# Keyboard_Controller register map
Vendor: Texas Instruments
Peripheral module from a debugger description file (folder omap4460).
Registers are 32-bit, read-only, reset 0x0 unless marked. A register's access mark holds for its fields unless they carry their own. Offsets are as the file gives them; lines under a group give offsets from that group; [hi:lo] are bit positions; {n}, {i} and the like mark numbered series; 'fields as' and 'values as' point back to an identical list; <NAME> marks a mode.

## Keyboard_Controller
0x00 KBD_REVISION reset not defined — This register contains the IP revision code.
  [31:0] REVISION — IP revision
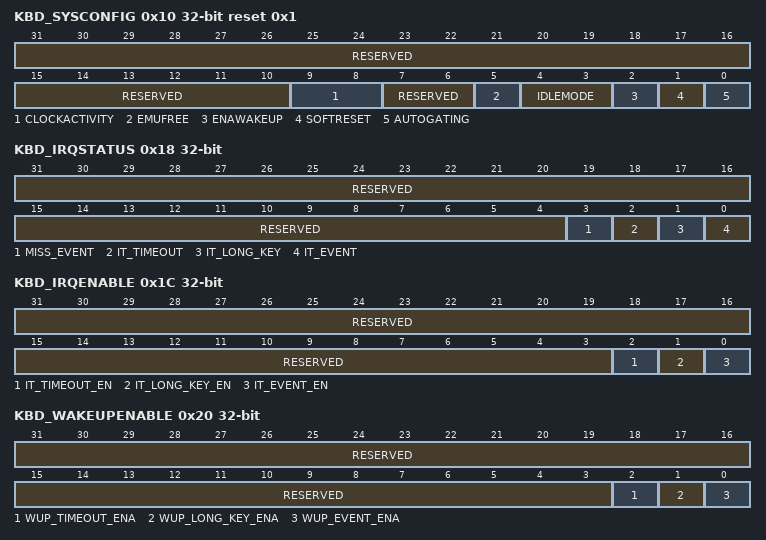
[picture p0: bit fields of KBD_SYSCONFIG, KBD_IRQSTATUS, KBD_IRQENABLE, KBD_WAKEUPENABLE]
0x10 KBD_SYSCONFIG rw reset 0x1 — This register controls the various parameters of the L4 interface.
  [31:10] RESERVED — Reads return 0.
  [9:8] CLOCKACTIVITY — Clock(s) activity during wake-up mode period.
    0=Functional clock can be switched off; L4 -nterface clock can be switched-off; 1=Functional clock can be switched off; L4 interface clock is maintained during wake-up period; 2=Functional clock is maintained during wake-up period; L4 interface clock can be switched off; 3=Functional clock is maintained during wake-up period; L4 interface clock is maintained during wake-up period
  [7:6] RESERVED — Write 0s for future compatibility.Reads return 0.
  [5] EMUFREE — Emulation mode
    0=The keyboard module is frozen in emulation mode (PINSUSPENDN signal active); 1=The keyboard module runs free, regardless of PINSUSPENDN value
  [4:3] IDLEMODE — Power management, req/ack control
    0=Force-idle. An idle request is acknowledged unconditionally.; 1=No-idle. An idle request is never acknowledged.; 2=Smart-idle. Acknowledgment to an idle request is given based on the internal activity of the module.; 3=Reserved.Do not use
  [2] ENAWAKEUP — Wake-up feature global control
    0=No wake-up line assertion in idle mode; 1=Wake-up line assertion enabled in smart-idle mode
  [1] SOFTRESET — Software reset. This bit is automatically reset by the hardware. During reads, it always return 0.
    0=Normal mode; 1=The module is reset
  [0] AUTOGATING — Internal L4 interface clock gating strategy
    0=L4 interface clock is free-running; 1=Automatic L4 interface clock gating strategy is applied, based on the L4 interface activity
0x14 KBD_SYSSTATUS — This register controls optional features specific to the timer function.
  [0] RESETDONE — Internal reset monitoring
    0=RESETDONE_0_r (Internal module reset is ongoing.); 1=RESETDONE_1_r (Reset completed)
0x18 KBD_IRQSTATUS rw — The keyboard interrupt-status register is used to determine which of the keyboard events requested an interrupt.
  [31:4] RESERVED — Reads return 0.
  [3] MISS_EVENT — Indicates when a miss event occurs.
    0=No miss event; 1=A miss event occurs
  [2] IT_TIMEOUT — Indicates when a time-out event is detected.
    0=No time-out event; 1=A time-out event occurs
  [1] IT_LONG_KEY — Indicates when a long-key event is detected.
    0=No long-key event; 1=A long-key event occurs
  [0] IT_EVENT — Indicates when an event is detected.
    0=No event; 1=An event occurs
0x1C KBD_IRQENABLE rw — The keyboard interrupt-enable register lets the user enable certain keyboard event for generating an interrupt request.
  [31:3] RESERVED — Reads return 0
  [2] IT_TIMEOUT_EN — Time-out interrupt enable
    0=Time-out interrupt disabled; 1=Time-out interrupt enabled
  [1] IT_LONG_KEY_EN — Long-key interrupt enable
    0=Long-key interrupt disabled; 1=Long-key interrupt enabled
  [0] IT_EVENT_EN — Enable event interrupt
    0=Event interrupt disabled; 1=Event interrupt enabled
0x20 KBD_WAKEUPENABLE rw — The keyboard wake-up enable register lets the user mask the expected source of wake-up event that generates a wake-up request.
  [31:3] RESERVED — Reads return 0.
  [2] WUP_TIMEOUT_ENA — Time-out wake-up enable
    0=Time-out wake-up generation disabled; 1=Time-out wake-up generation enabled
  [1] WUP_LONG_KEY_ENA — Long-key wake-up enable
    0=Long-key wake-up generation disabled; 1=Long-key wake-up generation enabled
  [0] WUP_EVENT_ENA — Event wake-up enable
    0=Event wake-up generation disabled; 1=Event wake-up generation enabled
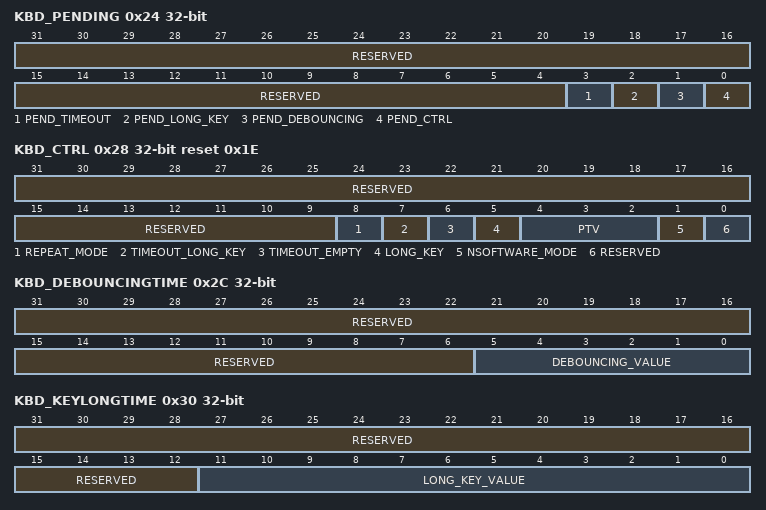
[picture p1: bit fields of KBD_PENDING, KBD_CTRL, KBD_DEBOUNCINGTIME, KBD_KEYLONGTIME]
0x24 KBD_PENDING — Software must read the pending write bits to ensure that following write access is not discarded due to ongoing write synchronization process.
  [31:4] RESERVED — Reads return 0.
  [3] PEND_TIMEOUT — Write-pending bit forKBD_TIMEOUT register
    0=PEND_TIMEOUT_0_r (No write pending to the register); 1=PEND_TIMEOUT_1_r (A write is pending to the register)
  [2] PEND_LONG_KEY — Write-pending bit forKBD_KEYLONGTIME register
    0=PEND_LONG_KEY_0_r (No write pending to the register.); 1=PEND_LONG_KEY_1_r (A write is pending to the register)
  [1] PEND_DEBOUNCING — Write-pending bit forKBD_DEBOUNCINGTIME register
    0=PEND_DEBOUNCING_0_r (No write pending to the register); 1=PEND_DEBOUNCING_1_r (A write is pending to the register)
  [0] PEND_CTRL — Write pending bit forKBD_CTRL register
    0=PEND_CTRL_0_r (No write pending to the register); 1=PEND_CTRL_1_r (A write is pending to the register)
0x28 KBD_CTRL rw reset 0x1E — This register sets the functional configuration of the module.
  [31:9] RESERVED — Reads return 0.
  [8] REPEAT_MODE — Repeat mode enable
    0=Repeat mode detection disabled; 1=Repeat mode detection enabled
  [7] TIMEOUT_LONG_KEY — Time-out long key mode enable
    0=Time-out long key mode disabled; 1=Time-out long key mode enabled
  [6] TIMEOUT_EMPTY — Time-out empty mode enable
    values as TIMEOUT_LONG_KEY
  [5] LONG_KEY — Long-key mode enable.
    0=Long-key mode disabled; 1=Long-key mode enabled
  [4:2] PTV — Prescale clock timer value
  [1] NSOFTWARE_MODE — Select hardware or software mode for key decoding.
    0=Enable software mode; 1=Enable hardware decoding using internal sequencer
  [0] RESERVED — Reads return 0.
0x2C KBD_DEBOUNCINGTIME rw — This register is used to filter glitches on the press key or release key.
  [31:6] RESERVED — Reads return 0.
  [5:0] DEBOUNCING_VALUE — This value corresponds to the desired value of debouncing time.
0x30 KBD_KEYLONGTIME rw — This register is used to measure duration of a key press to allow shortcut detection.
  [31:12] RESERVED — Reads return 0.
  [11:0] LONG_KEY_VALUE — This value corresponds to the desired value of the long-key interrupt or repeat mode value.
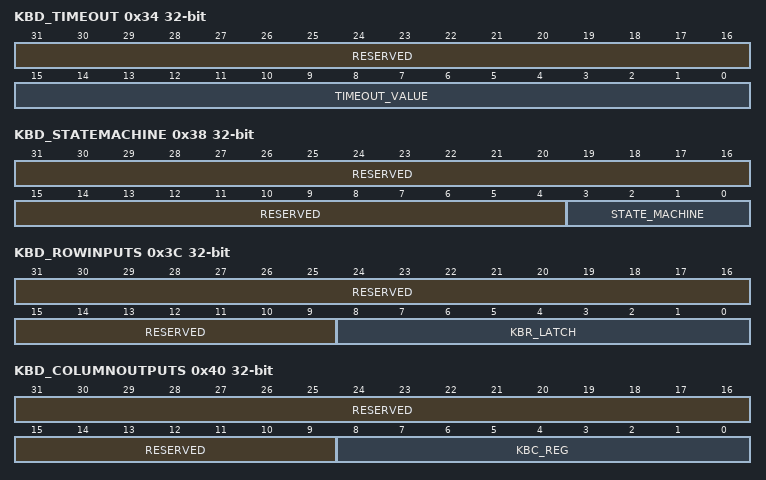
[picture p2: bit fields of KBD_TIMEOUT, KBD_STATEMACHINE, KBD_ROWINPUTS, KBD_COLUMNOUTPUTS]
0x34 KBD_TIMEOUT rw — This register is used to detect a long inactivity on the keyboard.
  [31:16] RESERVED — Reads return 0.
  [15:0] TIMEOUT_VALUE — This value corresponds to the desired value of the time-out interrupt.
0x38 KBD_STATEMACHINE — This register indicates the state of the sequencer.
  [31:4] RESERVED — Reads return 0.
  [3:0] STATE_MACHINE — The state of internal state machine. See, for details.
0x3C KBD_ROWINPUTS — This register stores the value of the row inputs.
  [31:9] RESERVED — Reads return 0.
  [8:0] KBR_LATCH — The value of the rows input.
0x40 KBD_COLUMNOUTPUTS rw — This register holds the value of the columns output.
  [31:9] RESERVED — Reads return 0.
  [8:0] KBC_REG — The value of the columns output
0x44 KBD_FULLCODE31_0 — The register codes the row 0, row 1, row 2, and row 3.
  [31:0] FULL_CODE_31_0 — A bit set to 1 indicates that the corresponding key is pressed.
0x48 KBD_FULLCODE63_32 — The register codes rows 4, 5, 6, and 7.
  [31:0] FULL_CODE_63_32 — A bit set to 1 indicates that the corresponding key is pressed.
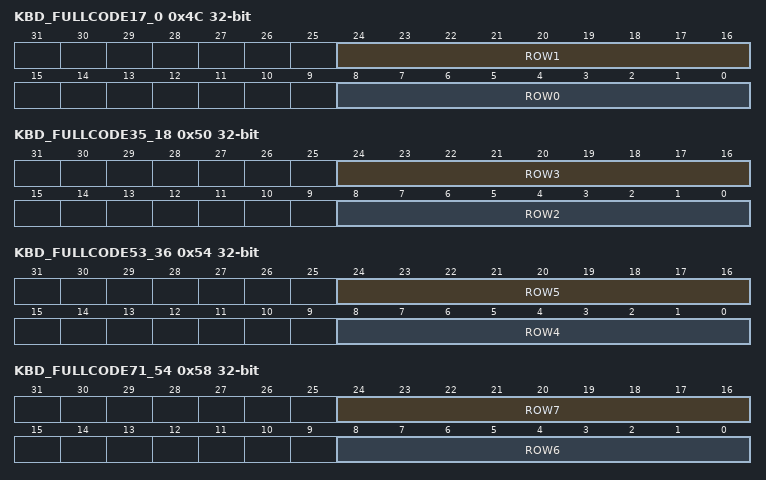
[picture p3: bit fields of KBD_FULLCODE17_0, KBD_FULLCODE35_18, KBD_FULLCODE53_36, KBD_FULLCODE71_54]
0x4C KBD_FULLCODE17_0 — The register codes row 0 and row 1. Row 0 is coded between bit 0 and 8; row 1 is coded between bit 24 and 16.
  [24:16] ROW1 — A bit set to 1 indicates that the corresponding key is pressed.
  [8:0] ROW0 — A bit set to 1 indicates that the corresponding key is pressed.
0x50 KBD_FULLCODE35_18 — The register codes row 2 and row 3. Row 2 is coded between bit 0 and 8; row 3 is coded between bit 24 and 16
  [24:16] ROW3 — A bit set to 1 indicates that the corresponding key is pressed.
  [8:0] ROW2 — A bit set to 1 indicates that the corresponding key is pressed.
0x54 KBD_FULLCODE53_36 — The register codes row 4 and row 5. Row 4 is coded between bit 0 and 8; row 5 is coded between bit 24 and 16.
  [24:16] ROW5 — A bit set to 1 indicates that the corresponding key is pressed.
  [8:0] ROW4 — A bit set to 1 indicates that the corresponding key is pressed.
0x58 KBD_FULLCODE71_54 — The register codes row 6 and row 7. Row 6 is coded between bit 0 and 8; row 7 is coded between bit 24 and 16.
  [24:16] ROW7 — A bit set to 1 indicates that the corresponding key is pressed.
  [8:0] ROW6 — A bit set to 1 indicates that the corresponding key is pressed.
0x5C KBD_FULLCODE80_72 — The register codes row 8. Row 8 is coded between bit 0 and 8.
  [8:0] ROW8 — A bit set to 1 indicates that the corresponding key is pressed.
